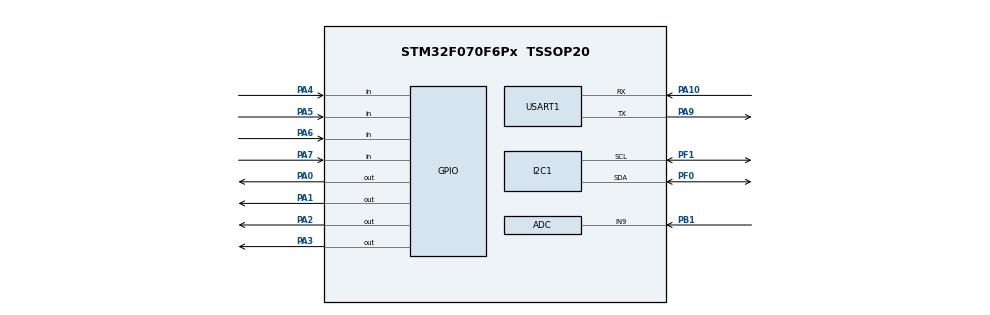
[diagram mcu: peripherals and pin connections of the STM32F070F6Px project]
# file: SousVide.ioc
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Mcu.Family=STM32F0
Mcu.Name=STM32F070F6Px
Mcu.Package=TSSOP20
PA0.Signal=GPIO_Output
PA1.Signal=GPIO_Output
PA10.Mode=Asynchronous
PA10.Signal=USART1_RX
PA13.Mode=Serial_Wire
PA13.Signal=SYS_SWDIO
PA14.Mode=Serial_Wire
PA14.Signal=SYS_SWCLK
PA2.Signal=GPIO_Output
PA3.Signal=GPIO_Output
PA4.Signal=GPIO_Input
PA5.Signal=GPIO_Input
PA6.Signal=GPIO_Input
PA7.Signal=GPIO_Input
PA9.Mode=Asynchronous
PA9.Signal=USART1_TX
PB1.Mode=IN9
PB1.Signal=ADC_IN9
PF0-OSC_IN.Mode=I2C
PF0-OSC_IN.Signal=I2C1_SDA
PF1-OSC_OUT.Mode=I2C
PF1-OSC_OUT.Signal=I2C1_SCL
ProjectManager.HeapSize=0x200
ProjectManager.StackSize=0x400
ProjectManager.TargetToolchain=MDK-ARM V5.27
USART1.VirtualMode=VM_ASYNC
board=custom

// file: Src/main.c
/* USER CODE BEGIN Header */
/**
  ******************************************************************************
  * @file           : main.c
  * @brief          : Main program body
  ******************************************************************************
  * @attention
  *
  * <h2><center>&copy; Copyright (c) 2020 STMicroelectronics.
  * All rights reserved.</center></h2>
  *
  * This software component is licensed by ST under BSD 3-Clause license,
  * the "License"; You may not use this file except in compliance with the
  * License. You may obtain a copy of the License at:
  *                        opensource.org/licenses/BSD-3-Clause
  *
  ******************************************************************************
  */
/* USER CODE END Header */

#include "main.h"
#include "adc.h"
#include "i2c.h"
#include "usart.h"
#include "gpio.h"

void SystemClock_Config(void);

int main(void)
{

  /* MCU Configuration--------------------------------------------------------*/

  /* Reset of all peripherals, Initializes the Flash interface and the Systick. */
  HAL_Init();

  /* Configure the system clock */
  SystemClock_Config();

  /* Initialize all configured peripherals */
  MX_GPIO_Init();
  MX_ADC_Init();
  MX_I2C1_Init();
  MX_USART1_UART_Init();
  /* USER CODE BEGIN 2 */

	//HAL_GPIO_WritePin(GPIOA,GPIO_PIN_3,GPIO_PIN_RESET);
	uint32_t bufferTimestamps[20];
  /* USER CODE END 2 */

  /* Infinite loop */
  while (1)
  {

    /* USER CODE BEGIN 3 */

		if(HAL_GPIO_ReadPin(GPIOA,GPIO_PIN_7) == 0)
		{
			/*
			HAL_Delay(4);
			HAL_GPIO_WritePin(GPIOA,GPIO_PIN_3,GPIO_PIN_SET);
			//HAL_Delay(1);
			while(HAL_GPIO_ReadPin(GPIOA,GPIO_PIN_7) == 1){}
			HAL_GPIO_WritePin(GPIOA,GPIO_PIN_3,GPIO_PIN_RESET);
			*/
			HAL_Delay(4);
			HAL_GPIO_WritePin(GPIOA,GPIO_PIN_3,GPIO_PIN_SET);
			HAL_Delay(1);
			HAL_GPIO_WritePin(GPIOA,GPIO_PIN_3,GPIO_PIN_RESET);

				/*
			for(uint8_t i=0;i<20;i++)
			{
				bufferTimestamps[i] = bufferTimestamps[i+1];
			}
			bufferTimestamps[19] = HAL_GetTick();
			*/
			//while(HAL_GPIO_ReadPin(GPIOA,GPIO_PIN_7) == 0){}
		}
  }
  /* USER CODE END 3 */
}

void SystemClock_Config(void)
{
  RCC_OscInitTypeDef RCC_OscInitStruct = {0};
  RCC_ClkInitTypeDef RCC_ClkInitStruct = {0};
  RCC_PeriphCLKInitTypeDef PeriphClkInit = {0};

  /** Initializes the CPU, AHB and APB busses clocks
  */
  RCC_OscInitStruct.OscillatorType = RCC_OSCILLATORTYPE_HSI|RCC_OSCILLATORTYPE_HSI14;
  RCC_OscInitStruct.HSIState = RCC_HSI_ON;
  RCC_OscInitStruct.HSI14State = RCC_HSI14_ON;
  RCC_OscInitStruct.HSICalibrationValue = RCC_HSICALIBRATION_DEFAULT;
  RCC_OscInitStruct.HSI14CalibrationValue = 16;
  RCC_OscInitStruct.PLL.PLLState = RCC_PLL_NONE;
  if (HAL_RCC_OscConfig(&RCC_OscInitStruct) != HAL_OK)
  {
    Error_Handler();
  }
  /** Initializes the CPU, AHB and APB busses clocks
  */
  RCC_ClkInitStruct.ClockType = RCC_CLOCKTYPE_HCLK|RCC_CLOCKTYPE_SYSCLK
                              |RCC_CLOCKTYPE_PCLK1;
  RCC_ClkInitStruct.SYSCLKSource = RCC_SYSCLKSOURCE_HSI;
  RCC_ClkInitStruct.AHBCLKDivider = RCC_SYSCLK_DIV1;
  RCC_ClkInitStruct.APB1CLKDivider = RCC_HCLK_DIV1;

  if (HAL_RCC_ClockConfig(&RCC_ClkInitStruct, FLASH_LATENCY_0) != HAL_OK)
  {
    Error_Handler();
  }
  PeriphClkInit.PeriphClockSelection = RCC_PERIPHCLK_USART1|RCC_PERIPHCLK_I2C1;
  PeriphClkInit.Usart1ClockSelection = RCC_USART1CLKSOURCE_PCLK1;
  PeriphClkInit.I2c1ClockSelection = RCC_I2C1CLKSOURCE_HSI;
  if (HAL_RCCEx_PeriphCLKConfig(&PeriphClkInit) != HAL_OK)
  {
    Error_Handler();
  }
}

void Error_Handler(void)
{
}

/************************ (C) COPYRIGHT STMicroelectronics *****END OF FILE****/
